# WKUP_PLLCTRL0 register map
Vendor: Texas Instruments
Peripheral module from a debugger description file (folder am65x).
Registers are 32-bit, read-write, reset 0x0 unless marked. A register's access mark holds for its fields unless they carry their own. Offsets are as the file gives them; lines under a group give offsets from that group; [hi:lo] are bit positions; {n}, {i} and the like mark numbered series; 'fields as' and 'values as' point back to an identical list; <NAME> marks a mode.

## WKUP_PLLCTRL0
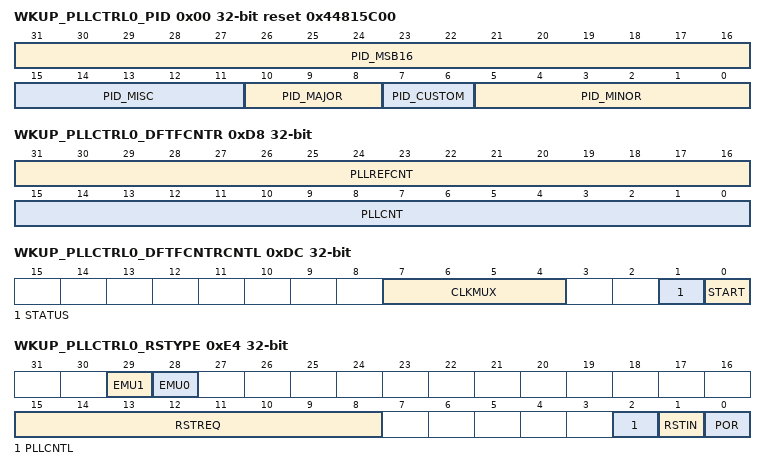
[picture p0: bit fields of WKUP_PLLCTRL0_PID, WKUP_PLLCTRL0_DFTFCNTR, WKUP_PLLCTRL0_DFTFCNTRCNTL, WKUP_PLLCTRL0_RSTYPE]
0x00 WKUP_PLLCTRL0_PID ro reset 0x44815C00 — register
  [31:16] PID_MSB16, [15:11] PID_MISC, [10:8] PID_MAJOR, [7:6] PID_CUSTOM, [5:0] PID_MINOR
0xD0 WKUP_PLLCTRL0_SHIFTDIV — Shift divider register
  [7:0] DIV_VALUE
0xD4 WKUP_PLLCTRL0_CS0 — Catscan control register
  [0] CS_CLK_START
0xD8 WKUP_PLLCTRL0_DFTFCNTR — DFT frequency counter register
  [31:16] PLLREFCNT, [15:0] PLLCNT
0xDC WKUP_PLLCTRL0_DFTFCNTRCNTL access per field — DFT frequency counter control register
  [7:4] CLKMUX rw, [1] STATUS ro, [0] START rw
0xE0 WKUP_PLLCTRL0_FUSERR ro reset not defined — Fusefarm error register
  [4:0] ERR
0xE4 WKUP_PLLCTRL0_RSTYPE ro reset not defined — Reset type status register
  [29] EMU1, [28] EMU0, [15:8] RSTREQ, [2] PLLCNTL, [1] RSTIN, [0] POR
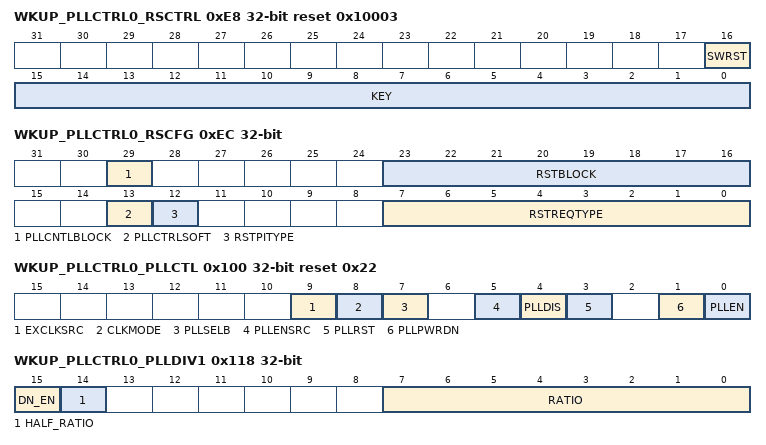
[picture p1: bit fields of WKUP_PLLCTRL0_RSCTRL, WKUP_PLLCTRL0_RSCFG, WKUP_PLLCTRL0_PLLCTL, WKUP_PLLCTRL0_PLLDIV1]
0xE8 WKUP_PLLCTRL0_RSCTRL reset 0x10003 — Reset control register
  [16] SWRST, [15:0] KEY
0xEC WKUP_PLLCTRL0_RSCFG — Reset control register
  [29] PLLCNTLBLOCK, [23:16] RSTBLOCK, [13] PLLCTRLSOFT, [12] RSTPITYPE, [7:0] RSTREQTYPE
0xF0 WKUP_PLLCTRL0_RSISO — Reset isolation control register
  [15:0] SYSCLKISO
0x100 WKUP_PLLCTRL0_PLLCTL reset 0x22 (reset mask 0x2A3) — PLL control register
  [9] EXCLKSRC, [8] CLKMODE, [7] PLLSELB, [5] PLLENSRC, [4] PLLDIS, [3] PLLRST, [1] PLLPWRDN, [0] PLLEN
0x110 WKUP_PLLCTRL0_PLLM reset not defined — PLL multiplier control register
  [7:0] _
0x118 WKUP_PLLCTRL0_PLLDIV1 (reset mask 0x4000) — PLL controller divider1 control register
  [15] DN_EN, [14] HALF_RATIO, [7:0] RATIO
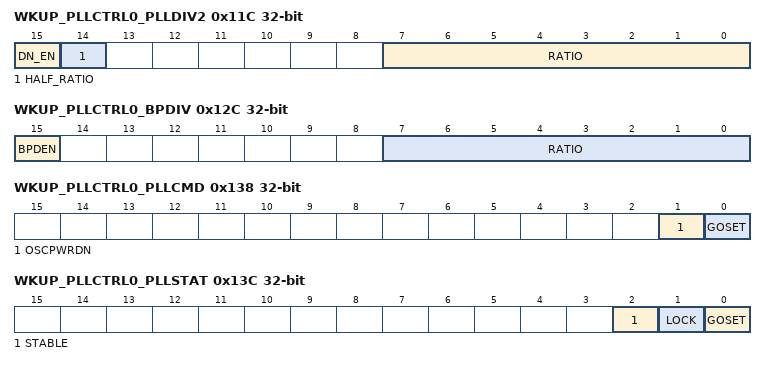
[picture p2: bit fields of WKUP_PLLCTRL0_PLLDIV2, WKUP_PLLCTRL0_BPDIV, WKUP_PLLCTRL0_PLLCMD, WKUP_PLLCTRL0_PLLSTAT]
0x11C WKUP_PLLCTRL0_PLLDIV2 (reset mask 0x4000) — PLL controller divider2 control register
  [15] DN_EN, [14] HALF_RATIO, [7:0] RATIO
0x12C WKUP_PLLCTRL0_BPDIV reset not defined — Bypass divider register
  [15] BPDEN, [7:0] RATIO
0x130 WKUP_PLLCTRL0_WAKEUP — Wakeup register
  [15:0] WKEN
0x138 WKUP_PLLCTRL0_PLLCMD — PLL Controller command register
  [1] OSCPWRDN, [0] GOSET
0x13C WKUP_PLLCTRL0_PLLSTAT ro (reset mask 0x3) — PLL Controller status register
  [2] STABLE, [1] LOCK, [0] GOSET
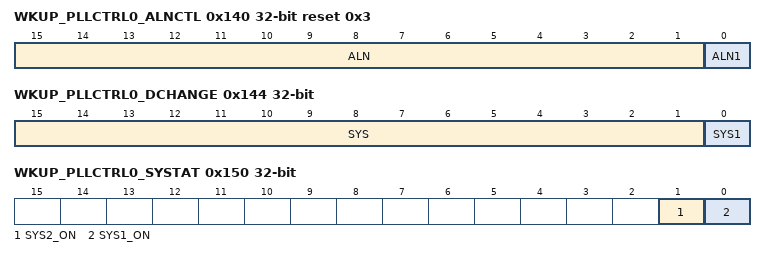
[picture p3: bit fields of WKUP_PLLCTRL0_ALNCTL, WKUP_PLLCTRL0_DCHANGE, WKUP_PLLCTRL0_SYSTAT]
0x140 WKUP_PLLCTRL0_ALNCTL reset 0x3 — PLL Controller clock align control register
  [15:1] ALN, [0] ALN1
0x144 WKUP_PLLCTRL0_DCHANGE ro — PLLDIV ratio change register
  [15:1] SYS, [0] SYS1
0x150 WKUP_PLLCTRL0_SYSTAT ro reset not defined — Sysclk status register
  [1] SYS2_ON, [0] SYS1_ON
